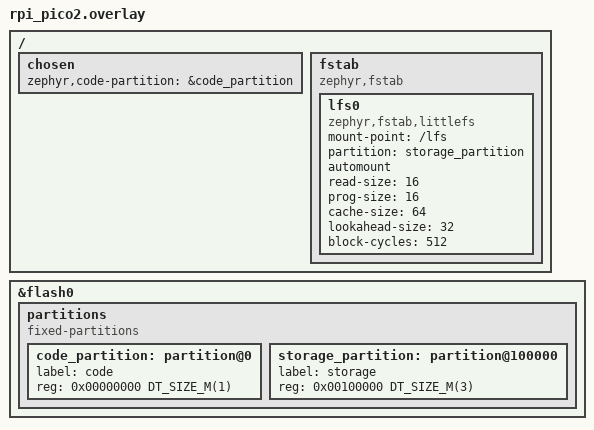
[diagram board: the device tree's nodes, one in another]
/ {
	chosen {
		zephyr,code-partition = &code_partition;
	};

	fstab {
		compatible = "zephyr,fstab";

		lfs0: lfs0 {
			compatible = "zephyr,fstab,littlefs";
			mount-point = "/lfs";
			partition = <&storage_partition>;
			automount;

			read-size = <16>;
			prog-size = <16>;
			cache-size = <64>;
			lookahead-size = <32>;
			block-cycles = <512>;
		};
	};
};

&flash0 {
	partitions {
		compatible = "fixed-partitions";
		#address-cells = <1>;
		#size-cells = <1>;

		/*
		 * 1 MiB application image
		 */
		code_partition: partition@0 {
			label = "code";
			reg = <0x00000000 DT_SIZE_M(1)>;
		};

		/*
		 * 3 MiB LittleFS (1 MiB code + 3 MiB storage = 4 MiB flash).
		 * Must start at 0x100000, not 0x300000 — see
		 * zephyr/dts/vendor/raspberrypi/partitions_4M_storage.dtsi.
		 */
		storage_partition: partition@100000 {
			label = "storage";
			reg = <0x00100000 DT_SIZE_M(3)>;
		};
	};
};
